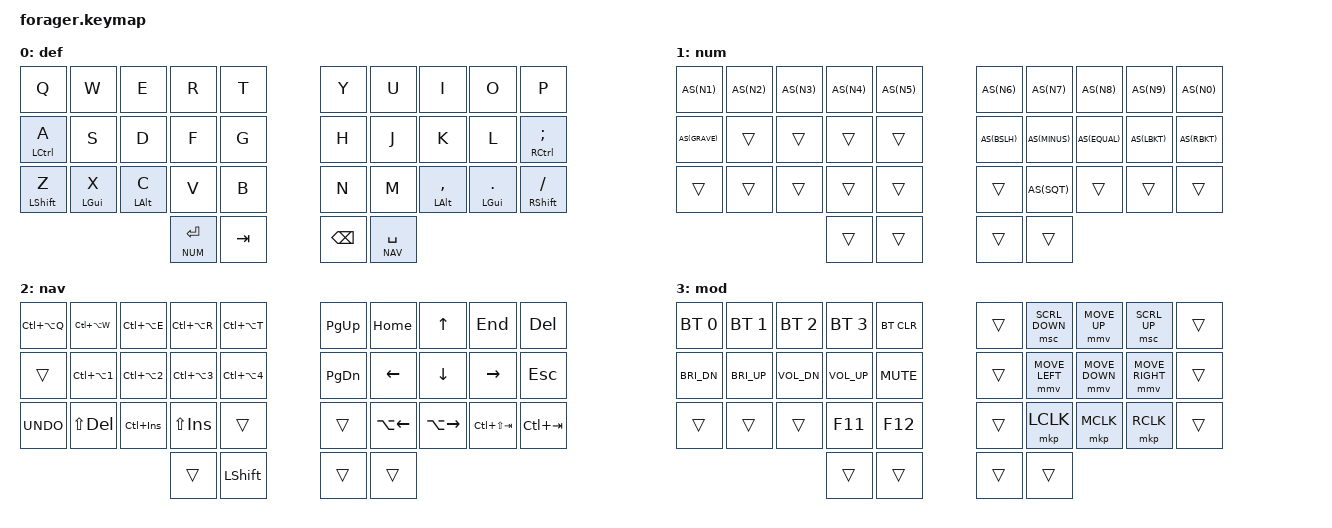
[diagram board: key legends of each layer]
#include <behaviors.dtsi>
#include <dt-bindings/zmk/keys.h>
#include <dt-bindings/zmk/bt.h>
#include <dt-bindings/zmk/outputs.h>
#include <dt-bindings/zmk/pointing.h>

#define DEF 0
#define NUM 1
#define NAV 2
#define MOD 3

#define AS(keycode) &as LS(keycode) keycode     // Autoshift Macro
#define MEH LS(LC(LALT))

&lt {
    compatible = "zmk,behavior-hold-tap";
    flavor = "balanced";
    tapping-term-ms = <200>;
    quick-tap-ms = <150>;
    // tapping-term-ms = <250>;
    // quick-tap-ms = <200>;
    // require-prior-idle-ms = <150>;
    hold-trigger-on-release;
};


/ {
    behaviors {
      as: auto_shift {
          compatible = "zmk,behavior-hold-tap";
          #binding-cells = <2>;
          tapping-term-ms = <250>;
          require-prior-idle-ms = <100>;
          flavor = "tap-preferred";
          bindings = <&kp>, <&kp>;
        };

      l_p: left_positional_hold_tap {
          compatible = "zmk,behavior-hold-tap";
          #binding-cells = <2>;
          flavor = "balanced";
          tapping-term-ms = <200>;
          quick-tap-ms = <150>;
          require-prior-idle-ms = <125>;
          bindings = <&kp>, <&kp>;
          hold-trigger-key-positions = <5 6 7 8 9 15 16 17 18 19 25 26 27 28 29 30 31 32 33>;
          hold-trigger-on-release;
        };

      r_p: right_positional_hold_tap {
          compatible = "zmk,behavior-hold-tap";
          #binding-cells = <2>;
          flavor = "balanced";
          tapping-term-ms = <200>;
          quick-tap-ms = <150>;
          require-prior-idle-ms = <125>;
          bindings = <&kp>, <&kp>;
          hold-trigger-key-positions = <0 1 2 3 4 10 11 12 13 14 20 21 22 23 24 30 31 32 33>;
          hold-trigger-on-release;
        };
    };

    combos {
        compatible = "zmk,combos";
        combo_esc {
            timeout-ms = <50>;
            key-positions = <11 12>;
            bindings = <&kp ESC>;
        };
        combo_cesc {
            timeout-ms = <50>;
            key-positions = <17 18>;
            bindings = <&kp LC(ESC)>;
        };
        combo_capsword {
            timeout-ms = <50>;
            key-positions = <20 29>;
            bindings = <&caps_word>;
        };
        combo_bootloader {
            timeout-ms = <50>;
            key-positions = <0 9>;
            bindings = <&bootloader>;
        };
    };

    conditional_layers {
        compatible = "zmk,conditional-layers";
        mod_layer {
            if-layers = <NUM NAV>;
            then-layer = <MOD>;
        };
    };

  keymap {
    compatible = "zmk,keymap";

    def {
      bindings = <
        &kp Q          &kp W         &kp E         &kp R          &kp T                                           &kp Y           &kp U          &kp I              &kp O            &kp P
        &l_p LCTRL A   &kp S         &kp D         &kp F          &kp G                                           &kp H           &kp J          &kp K              &kp L            &r_p RCTRL SEMI
        &l_p LSHFT Z   &l_p LGUI X   &l_p LALT C   &kp V          &kp B                                           &kp N           &kp M          &r_p LALT COMMA    &r_p LGUI DOT    &r_p RSHFT FSLH
                                                                  &lt NUM ENTER   &kp TAB      &kp BSPC   &lt NAV SPACE
      >;
    };

    num {
      bindings = <
        AS(N1)        AS(N2)         AS(N3)         AS(N4)          AS(N5)                                     AS(N6)     AS(N7)          AS(N8)          AS(N9)          AS(N0)
        AS(GRAVE)     &trans         &trans         &trans          &trans                                     AS(BSLH)   AS(MINUS)       AS(EQUAL)       AS(LBKT)        AS(RBKT)
        &trans        &trans         &trans         &trans          &trans                                     &trans     AS(SQT)         &trans          &trans          &trans
                                                                    &trans        &trans           &trans      &trans
      >;
    };

    nav {
      bindings = <
        &kp LC(LA(Q)) &kp LC(LA(W))  &kp LC(LA(E))   &kp LC(LA(R))  &kp LC(LA(T))                              &kp PAGE_UP     &kp HOME        &kp UP          &kp END         &kp DELETE
        &trans        &kp LC(LA(N1)) &kp LC(LA(N2))  &kp LC(LA(N3)) &kp LC(LA(N4))                             &kp PAGE_DOWN   &kp LEFT        &kp DOWN        &kp RIGHT       &kp ESC
        &kp K_UNDO    &kp LS(DEL)    &kp LC(INS)     &kp LS(INS)    &trans                                     &trans          &kp LA(LEFT)    &kp LA(RIGHT)   &kp LC(LS(TAB)) &kp LC(TAB)
                                                                    &trans         &kp LSHFT       &trans      &trans
      >;
    };
    
    mod {
      bindings = <
        &bt BT_SEL 0    &bt BT_SEL 1 &bt BT_SEL 2    &bt BT_SEL 3    &bt BT_CLR                                &trans          &msc SCRL_DOWN  &mmv MOVE_UP    &msc SCRL_UP    &trans
        &kp C_BRI_DN    &kp C_BRI_UP &kp C_VOL_DN    &kp C_VOL_UP    &kp C_MUTE                                &trans          &mmv MOVE_LEFT  &mmv MOVE_DOWN  &mmv MOVE_RIGHT &trans
        &trans          &trans       &trans          &kp F11         &kp F12                                   &trans          &mkp LCLK       &mkp MCLK       &mkp RCLK       &trans
                                                                     &trans          &trans          &trans    &trans
      >;
    };
        
  };
};
